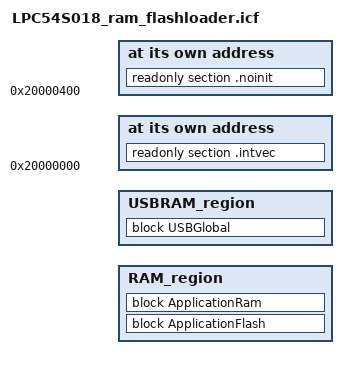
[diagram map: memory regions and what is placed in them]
/*
** ###################################################################
**     Processors:          LPC54S018JBD208
**                          LPC54S018JET180
**
**     Compiler:            IAR ANSI C/C++ Compiler for ARM
**
**     Abstract:
**         Linker file for the IAR ANSI C/C++ Compiler for ARM
**
**     Copyright (c) 2015 Freescale Semiconductor, Inc.
**     Copyright 2016-2018 NXP
**     All rights reserved.
**     
**     SPDX-License-Identifier: BSD-3-Clause
**
**     http:                 www.nxp.com
**     mail:                 support@nxp.com
**
** ###################################################################
*/

/*-Memory Regions-*/
define symbol __ICFEDIT_region_ROM_start__ = 0x0;
define symbol __ICFEDIT_region_ROM_end__   = __ICFEDIT_region_ROM_start__ + (512*1024);
define symbol __ICFEDIT_region_RAM_start__ = 0x20000000;
define symbol __ICFEDIT_region_RAM_end__   = __ICFEDIT_region_RAM_start__ + (64*1024);
define symbol __ICFEDIT_region_USBRAM_start__   = 0x40100000;
define symbol __ICFEDIT_region_USBRAM_end__ = __ICFEDIT_region_USBRAM_start__ + (8 * 1024);
/*-Specials-*/
define symbol __ICFEDIT_intvec_start__     = __ICFEDIT_region_RAM_start__;

/*-Sizes-*/
define symbol __ICFEDIT_size_cstack__ = (4*1024);
define symbol __ICFEDIT_size_heap__   = (0*1024);

/* Stack and Heap Sizes */
if (isdefinedsymbol(__stack_size__)) {
  define symbol __size_cstack__        = __stack_size__;
} else {
  define symbol __size_cstack__        = 0x1000;
}

if (isdefinedsymbol(__heap_size__)) {
  define symbol __size_heap__          = __heap_size__;
} else {
  define symbol __size_heap__          = 0x0;
}

define exported symbol __VECTOR_TABLE      = __ICFEDIT_intvec_start__;
define exported symbol __VECTOR_RAM        = __ICFEDIT_intvec_start__;

define exported symbol __BOOT_STACK_ADDRESS = __ICFEDIT_region_RAM_end__ - 8;

define symbol __code_start__ = __ICFEDIT_intvec_start__ + 0x400;

define memory mem with size = 4G;
define region ROM_region   = mem:[from __ICFEDIT_region_ROM_start__   to __ICFEDIT_region_ROM_end__];
define region RAM_region   = mem:[from __ICFEDIT_region_RAM_start__   to __ICFEDIT_region_RAM_end__];
define region USBRAM_region   = mem:[from __ICFEDIT_region_USBRAM_start__   to __ICFEDIT_region_USBRAM_end__];

define block CSTACK    with alignment = 8, size = __ICFEDIT_size_cstack__   { };
define block HEAP      with alignment = 8, size = __ICFEDIT_size_heap__     { };

initialize manually { readwrite };
initialize manually { section .data};
initialize manually { section .textrw };
do not initialize  { section .noinit, section m_usb_bdt, section m_usb_global };

define block USBGlobal {section m_usb_bdt, section m_usb_global};
define block CodeRelocate { section .textrw_init };
define block CodeRelocateRam { section .textrw };
place at address mem:__ICFEDIT_intvec_start__ { readonly section .intvec };
place at address mem:__code_start__ { readonly section .noinit };

define block ApplicationFlash { readonly, block CodeRelocate };
place in RAM_region   { block ApplicationFlash };

define block ApplicationRam { readwrite, block CodeRelocateRam,
                             block CSTACK, block HEAP };
place in RAM_region   { block ApplicationRam };
place in USBRAM_region   { block USBGlobal };
